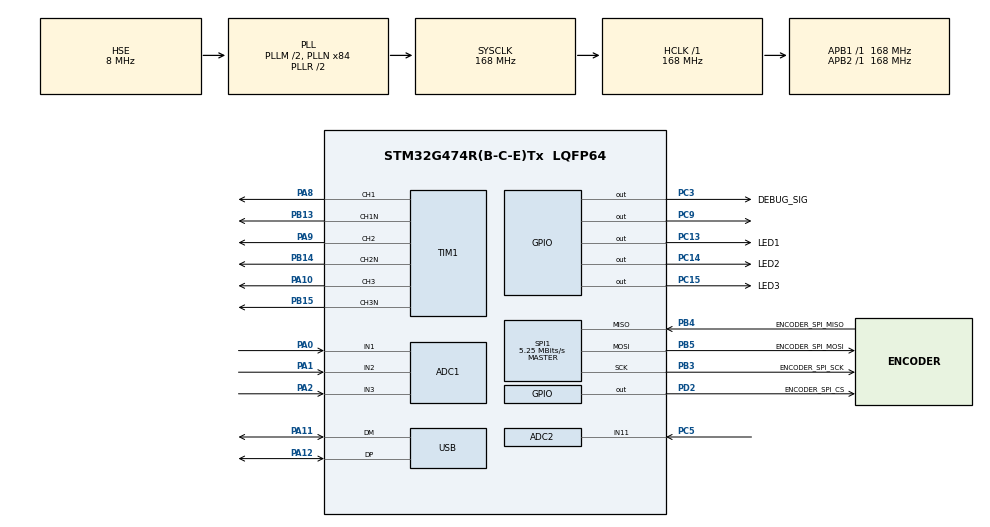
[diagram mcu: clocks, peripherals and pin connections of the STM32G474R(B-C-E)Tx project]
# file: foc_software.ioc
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ADC1.EnableInjectedConversion=ENABLE
ADC1.EnableRegularConversion=DISABLE
ADC1.ExternalTrigInjecConv=ADC_EXTERNALTRIGINJEC_T1_CC4
ADC1.ExternalTrigInjecConvEdge=ADC_EXTERNALTRIGINJECCONV_EDGE_FALLING
ADC1.InjNumberOfConversion=3
ADC1.InjectedChannel-3\#ChannelInjectedConversion=ADC_CHANNEL_1
ADC1.InjectedChannel-4\#ChannelInjectedConversion=ADC_CHANNEL_2
ADC1.InjectedChannel-5\#ChannelInjectedConversion=ADC_CHANNEL_3
ADC1.InjectedOffsetNumber-3\#ChannelInjectedConversion=ADC_OFFSET_NONE
ADC1.InjectedOffsetNumber-4\#ChannelInjectedConversion=ADC_OFFSET_NONE
ADC1.InjectedOffsetNumber-5\#ChannelInjectedConversion=ADC_OFFSET_NONE
ADC1.InjectedRank-3\#ChannelInjectedConversion=1
ADC1.InjectedRank-4\#ChannelInjectedConversion=2
ADC1.InjectedRank-5\#ChannelInjectedConversion=3
ADC1.InjectedSamplingTime-3\#ChannelInjectedConversion=ADC_SAMPLETIME_47CYCLES_5
ADC1.InjectedSamplingTime-4\#ChannelInjectedConversion=ADC_SAMPLETIME_47CYCLES_5
ADC1.InjectedSamplingTime-5\#ChannelInjectedConversion=ADC_SAMPLETIME_47CYCLES_5
ADC1.Rank1_Channel=ADC_CHANNEL_1
ADC1.Rank2_Channel=ADC_CHANNEL_2
ADC1.Rank3_Channel=ADC_CHANNEL_3
ADC1.master=1
ADC2.EnableInjectedConversion=ENABLE
ADC2.EnableRegularConversion=DISABLE
ADC2.ExternalTrigInjecConv=ADC_EXTERNALTRIGINJEC_T1_CC4
ADC2.ExternalTrigInjecConvEdge=ADC_EXTERNALTRIGINJECCONV_EDGE_FALLING
ADC2.InjNumberOfConversion=1
ADC2.InjectedChannel-1\#ChannelInjectedConversion=ADC_CHANNEL_11
ADC2.InjectedOffsetNumber-1\#ChannelInjectedConversion=ADC_OFFSET_NONE
ADC2.InjectedRank-1\#ChannelInjectedConversion=1
ADC2.InjectedSamplingTime-1\#ChannelInjectedConversion=ADC_SAMPLETIME_47CYCLES_5
ADC2.Rank1_Channel=ADC_CHANNEL_11
FREERTOS.Tasks01=defaultTask,24,128,StartDefaultTask,As weak,NULL,Dynamic,NULL,NULL
Mcu.Family=STM32G4
Mcu.Name=STM32G474R(B-C-E)Tx
Mcu.Package=LQFP64
Mcu.UserConstants=TIM_1_8_PERIOD_CLOCKS,3500;TIM_APB1_CLOCK_HZ,168000000;TIM_APB1_DEADTIME_CLOCKS,40;TIM_APB1_PERIOD_CLOCKS,4096;TIM_1_8_RCR,2;TIM_1_8_DEADTIME_CLOCKS,20;TIM_1_8_CLOCK_HZ,168000000
NVIC.PriorityGroup=NVIC_PRIORITYGROUP_4
NVIC.TIM1_UP_TIM16_IRQn=true\:5\:0\:false\:false\:true\:true\:true\:true\:true
NVIC.TIM6_DAC_IRQn=true\:15\:0\:false\:false\:true\:false\:false\:true\:true
NVIC.TimeBase=TIM6_DAC_IRQn
NVIC.TimeBaseIP=TIM6
NVIC.USB_LP_IRQn=true\:5\:0\:false\:false\:true\:true\:false\:true\:true
PA0.Mode=IN1-Single-Ended
PA0.Signal=ADC1_IN1
PA1.Mode=IN2-Single-Ended
PA1.Signal=ADC1_IN2
PA10.Signal=S_TIM1_CH3
PA11.Mode=Device
PA11.Signal=USB_DM
PA12.Mode=Device
PA12.Signal=USB_DP
PA13.Mode=Serial_Wire
PA13.Signal=SYS_JTMS-SWDIO
PA14.Mode=Serial_Wire
PA14.Signal=SYS_JTCK-SWCLK
PA2.Mode=IN3-Single-Ended
PA2.Signal=ADC1_IN3
PA8.Signal=S_TIM1_CH1
PA9.Signal=S_TIM1_CH2
PB13.Mode=PWM Generation1 CH1 CH1N
PB13.Signal=TIM1_CH1N
PB14.Mode=PWM Generation2 CH2 CH2N
PB14.Signal=TIM1_CH2N
PB15.Mode=PWM Generation3 CH3 CH3N
PB15.Signal=TIM1_CH3N
PB3.GPIO_Label=ENCODER_SPI_SCK
PB3.Mode=Full_Duplex_Master
PB3.Signal=SPI1_SCK
PB4.GPIO_Label=ENCODER_SPI_MISO
PB4.Mode=Full_Duplex_Master
PB4.Signal=SPI1_MISO
PB5.GPIO_Label=ENCODER_SPI_MOSI
PB5.Mode=Full_Duplex_Master
PB5.Signal=SPI1_MOSI
PC13.GPIO_Label=LED1
PC13.Signal=GPIO_Output
PC14-OSC32_IN.GPIO_Label=LED2
PC14-OSC32_IN.Signal=GPIO_Output
PC15-OSC32_OUT.GPIO_Label=LED3
PC15-OSC32_OUT.Signal=GPIO_Output
PC3.GPIO_Label=DEBUG_SIG
PC3.Signal=GPIO_Output
PC5.Mode=IN11-Single-Ended
PC5.Signal=ADC2_IN11
PC9.Signal=GPIO_Output
PD2.GPIO_Label=ENCODER_SPI_CS
PD2.Signal=GPIO_Output
PF0-OSC_IN.Mode=HSE-External-Oscillator
PF0-OSC_IN.Signal=RCC_OSC_IN
PF1-OSC_OUT.Mode=HSE-External-Oscillator
PF1-OSC_OUT.Signal=RCC_OSC_OUT
ProjectManager.HeapSize=0x200
ProjectManager.StackSize=0x400
ProjectManager.TargetToolchain=MDK-ARM V5.32
RCC.ADC12Freq_Value=168000000
RCC.ADC345Freq_Value=168000000
RCC.AHBFreq_Value=168000000
RCC.APB1Freq_Value=168000000
RCC.APB1TimFreq_Value=168000000
RCC.APB2Freq_Value=168000000
RCC.APB2TimFreq_Value=168000000
RCC.CK48CLockSelection=RCC_USBCLKSOURCE_HSI48
RCC.CortexFreq_Value=168000000
RCC.EXTERNAL_CLOCK_VALUE=12288000
RCC.HCLKFreq_Value=168000000
RCC.HSE_VALUE=8000000
RCC.HSI48_VALUE=48000000
RCC.HSI_VALUE=16000000
RCC.LSE_VALUE=32768
RCC.PLLM=RCC_PLLM_DIV2
RCC.PLLN=84
RCC.PLLQ=RCC_PLLQ_DIV4
RCC.PLLSourceVirtual=RCC_PLLSOURCE_HSE
RCC.SYSCLKFreq_VALUE=168000000
RCC.SYSCLKSource=RCC_SYSCLKSOURCE_PLLCLK
RCC.USBFreq_Value=48000000
RCC.VCOOutputFreq_Value=336000000
SH.S_TIM1_CH1.0=TIM1_CH1,PWM Generation1 CH1 CH1N
SH.S_TIM1_CH2.0=TIM1_CH2,PWM Generation2 CH2 CH2N
SH.S_TIM1_CH3.0=TIM1_CH3,PWM Generation3 CH3 CH3N
SPI1.BaudRatePrescaler=SPI_BAUDRATEPRESCALER_32
SPI1.CLKPhase=SPI_PHASE_2EDGE
SPI1.CLKPolarity=SPI_POLARITY_HIGH
SPI1.CalculateBaudRate=5.25 MBits/s
SPI1.DataSize=SPI_DATASIZE_16BIT
SPI1.Direction=SPI_DIRECTION_2LINES
SPI1.Mode=SPI_MODE_MASTER
SPI1.VirtualType=VM_MASTER
TIM1.Channel-PWM\ Generation1\ CH1\ CH1N=TIM_CHANNEL_1
TIM1.Channel-PWM\ Generation2\ CH2\ CH2N=TIM_CHANNEL_2
TIM1.Channel-PWM\ Generation3\ CH3\ CH3N=TIM_CHANNEL_3
TIM1.Channel-PWM\ Generation4\ No\ Output=TIM_CHANNEL_4
TIM1.CounterMode=TIM_COUNTERMODE_CENTERALIGNED2
TIM1.PeriodNoDither=TIM_1_8_PERIOD_CLOCKS
TIM1.RepetitionCounter=TIM_1_8_RCR
USB_DEVICE.CLASS_NAME_FS=CDC
USB_DEVICE.VirtualMode=Cdc
USB_DEVICE.VirtualModeFS=Cdc_FS
VP_FREERTOS_VS_CMSIS_V2.Mode=CMSIS_V2
VP_SYS_VS_DBSignals.Mode=DisableDeadBatterySignals
VP_SYS_VS_tim6.Mode=TIM6
VP_TIM1_VS_no_output4.Mode=PWM Generation4 No Output
VP_USB_DEVICE_VS_USB_DEVICE_CDC_FS.Mode=CDC_FS
board=custom

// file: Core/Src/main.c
/* USER CODE BEGIN Header */
/**
  ******************************************************************************
  * @file           : main.c
  * @brief          : Main program body
  ******************************************************************************
  * @attention
  *
  * Copyright (c) 2024 STMicroelectronics.
  * All rights reserved.
  *
  * This software is licensed under terms that can be found in the LICENSE file
  * in the root directory of this software component.
  * If no LICENSE file comes with this software, it is provided AS-IS.
  *
  **********************************VS

  ********************************************
  */
/* USER CODE END Header */
#include "main.h"
#include "cmsis_os.h"
#include "adc.h"
#include "spi.h"
#include "tim.h"
#include "usb_device.h"
#include "gpio.h"

/* USER CODE BEGIN Includes */
#include "drv_led.h"
#include "drv_encoder.h"
#include "vofa.h"
#include "low_level.h"
#include "board.h"

/* USER CODE END Includes */

void SystemClock_Config(void);
void MX_FREERTOS_Init(void);

int main(void)
{

  /* MCU Configuration--------------------------------------------------------*/

  /* Reset of all peripherals, Initializes the Flash interface and the Systick. */
  HAL_Init();

  /* Configure the system clock */
  SystemClock_Config();

  /* Initialize all configured peripherals */
  MX_GPIO_Init();
  MX_SPI1_Init();
  MX_TIM1_Init();
  MX_ADC1_Init();
  MX_ADC2_Init();
  /* USER CODE BEGIN 2 */
  board_init();
  start_pwm_adc();

  /* USER CODE END 2 */

  /* Init scheduler */
  osKernelInitialize();

  /* Call init function for freertos objects (in cmsis_os2.c) */
  MX_FREERTOS_Init();

  /* Start scheduler */
  osKernelStart();

  /* We should never get here as control is now taken by the scheduler */

  /* Infinite loop */
  while (1)
  {

    /* USER CODE BEGIN 3 */
    //mt6825.sample_now();
    //mt6825.update();

	  // led1.toggle();
	  // HAL_Delay(200);
	  // led2.toggle();
	  // HAL_Delay(200);
	  // led3.toggle();
	  // HAL_Delay(200);
  }
  /* USER CODE END 3 */
}

void SystemClock_Config(void)
{
  RCC_OscInitTypeDef RCC_OscInitStruct = {0};
  RCC_ClkInitTypeDef RCC_ClkInitStruct = {0};

  /** Configure the main internal regulator output voltage
  */
  HAL_PWREx_ControlVoltageScaling(PWR_REGULATOR_VOLTAGE_SCALE1_BOOST);

  /** Initializes the RCC Oscillators according to the specified parameters
  * in the RCC_OscInitTypeDef structure.
  */
  RCC_OscInitStruct.OscillatorType = RCC_OSCILLATORTYPE_HSI48|RCC_OSCILLATORTYPE_HSE;
  RCC_OscInitStruct.HSEState = RCC_HSE_ON;
  RCC_OscInitStruct.HSI48State = RCC_HSI48_ON;
  RCC_OscInitStruct.PLL.PLLState = RCC_PLL_ON;
  RCC_OscInitStruct.PLL.PLLSource = RCC_PLLSOURCE_HSE;
  RCC_OscInitStruct.PLL.PLLM = RCC_PLLM_DIV2;
  RCC_OscInitStruct.PLL.PLLN = 84;
  RCC_OscInitStruct.PLL.PLLP = RCC_PLLP_DIV2;
  RCC_OscInitStruct.PLL.PLLQ = RCC_PLLQ_DIV4;
  RCC_OscInitStruct.PLL.PLLR = RCC_PLLR_DIV2;
  if (HAL_RCC_OscConfig(&RCC_OscInitStruct) != HAL_OK)
  {
    Error_Handler();
  }

  /** Initializes the CPU, AHB and APB buses clocks
  */
  RCC_ClkInitStruct.ClockType = RCC_CLOCKTYPE_HCLK|RCC_CLOCKTYPE_SYSCLK
                              |RCC_CLOCKTYPE_PCLK1|RCC_CLOCKTYPE_PCLK2;
  RCC_ClkInitStruct.SYSCLKSource = RCC_SYSCLKSOURCE_PLLCLK;
  RCC_ClkInitStruct.AHBCLKDivider = RCC_SYSCLK_DIV1;
  RCC_ClkInitStruct.APB1CLKDivider = RCC_HCLK_DIV1;
  RCC_ClkInitStruct.APB2CLKDivider = RCC_HCLK_DIV1;

  if (HAL_RCC_ClockConfig(&RCC_ClkInitStruct, FLASH_LATENCY_4) != HAL_OK)
  {
    Error_Handler();
  }
}

void HAL_TIM_PeriodElapsedCallback(TIM_HandleTypeDef *htim)
{
  if (htim->Instance == TIM6) {
    HAL_IncTick();
  }
  /* USER CODE BEGIN Callback 1 */
  if (htim->Instance == TIM1) {
	tim1_period_elapsed_callback();
  }
  /* USER CODE END Callback 1 */
}

void Error_Handler(void)
{
  __disable_irq();
  while (1)
  {
  }
}

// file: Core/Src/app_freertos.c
/* USER CODE BEGIN Header */
/**
  ******************************************************************************
  * File Name          : app_freertos.c
  * Description        : Code for freertos applications
  ******************************************************************************
  * @attention
  *
  * Copyright (c) 2024 STMicroelectronics.
  * All rights reserved.
  *
  * This software is licensed under terms that can be found in the LICENSE file
  * in the root directory of this software component.
  * If no LICENSE file comes with this software, it is provided AS-IS.
  *
  ******************************************************************************
  */
/* USER CODE END Header */

#include "FreeRTOS.h"
#include "task.h"
#include "main.h"
#include "cmsis_os.h"

/* USER CODE BEGIN Includes */
#include "usb_device.h"
#include "axis.h"
/* USER CODE END Includes */

/* Definitions for defaultTask */
osThreadId_t defaultTaskHandle;
const osThreadAttr_t defaultTask_attributes = {
  .name = "defaultTask",
  .priority = (osPriority_t) osPriorityNormal,
  .stack_size = 128 * 4
};

void StartDefaultTask(void *argument);

void MX_FREERTOS_Init(void); /* (MISRA C 2004 rule 8.1) */

void MX_FREERTOS_Init(void) {

  /* Create the thread(s) */
  /* creation of defaultTask */
  defaultTaskHandle = osThreadNew(StartDefaultTask, NULL, &defaultTask_attributes);

}

__weak void StartDefaultTask(void *argument)
{
  /* init code for USB_Device */
  MX_USB_Device_Init();
  /* USER CODE BEGIN StartDefaultTask */
  start_thread();
  /* Infinite loop */
  for(;;)
  {
    osDelay(1);
  }
  /* USER CODE END StartDefaultTask */
}
